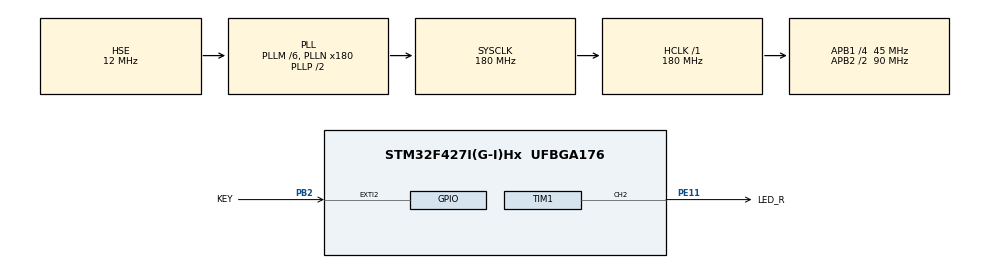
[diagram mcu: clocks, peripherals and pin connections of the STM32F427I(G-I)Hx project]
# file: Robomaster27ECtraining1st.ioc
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IWDG.Prescaler=IWDG_PRESCALER_16
IWDG.Reload=4000-1
Mcu.Family=STM32F4
Mcu.Name=STM32F427I(G-I)Hx
Mcu.Package=UFBGA176
NVIC.EXTI2_IRQn=true\:0\:0\:false\:false\:true\:true\:true\:true
NVIC.PriorityGroup=NVIC_PRIORITYGROUP_4
NVIC.TIM1_UP_TIM10_IRQn=true\:0\:0\:false\:false\:true\:true\:true\:true
PA13.Mode=Serial_Wire
PA13.Signal=SYS_JTMS-SWDIO
PA14.Mode=Serial_Wire
PA14.Signal=SYS_JTCK-SWCLK
PB2/BOOT1.GPIO_Label=KEY
PB2/BOOT1.GPIO_PuPd=GPIO_PULLDOWN
PB2/BOOT1.Signal=GPXTI2
PE11.GPIO_Label=LED_R
PE11.Signal=S_TIM1_CH2
PH0/OSC_IN.Mode=HSE-External-Oscillator
PH0/OSC_IN.Signal=RCC_OSC_IN
PH1/OSC_OUT.Mode=HSE-External-Oscillator
PH1/OSC_OUT.Signal=RCC_OSC_OUT
ProjectManager.HeapSize=0x200
ProjectManager.StackSize=0x400
ProjectManager.TargetToolchain=MDK-ARM V5.32
RCC.48MHZClocksFreq_Value=90000000
RCC.AHBFreq_Value=180000000
RCC.APB1CLKDivider=RCC_HCLK_DIV4
RCC.APB1Freq_Value=45000000
RCC.APB1TimFreq_Value=90000000
RCC.APB2CLKDivider=RCC_HCLK_DIV2
RCC.APB2Freq_Value=90000000
RCC.APB2TimFreq_Value=180000000
RCC.CortexFreq_Value=180000000
RCC.HCLKFreq_Value=180000000
RCC.HSE_VALUE=12000000
RCC.HSI_VALUE=16000000
RCC.LSE_VALUE=32768
RCC.PLLM=6
RCC.PLLN=180
RCC.PLLSourceVirtual=RCC_PLLSOURCE_HSE
RCC.SYSCLKFreq_VALUE=180000000
RCC.SYSCLKSource=RCC_SYSCLKSOURCE_PLLCLK
RCC.VCOOutputFreq_Value=360000000
SH.S_TIM1_CH2.0=TIM1_CH2,PWM Generation2 CH2
TIM1.Channel-PWM\ Generation2\ CH2=TIM_CHANNEL_2
TIM1.OCMode_PWM-PWM\ Generation2\ CH2=TIM_OCMODE_PWM2
TIM1.Period=1000-1
TIM1.Prescaler=180-1
TIM1.Pulse-PWM\ Generation2\ CH2=500
VP_IWDG_VS_IWDG.Mode=IWDG_Activate
VP_TIM1_VS_ClockSourceINT.Mode=Internal
board=custom

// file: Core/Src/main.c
/* USER CODE BEGIN Header */
/**
  ******************************************************************************
  * @file           : main.c
  * @brief          : Main program body
  ******************************************************************************
  * @attention
  *
  * Copyright (c) 2026 STMicroelectronics.
  * All rights reserved.
  *
  * This software is licensed under terms that can be found in the LICENSE file
  * in the root directory of this software component.
  * If no LICENSE file comes with this software, it is provided AS-IS.
  *
  ******************************************************************************
  */
/* USER CODE END Header */
#include "main.h"
#include "iwdg.h"
#include "tim.h"
#include "gpio.h"

uint8_t requested_mode;
uint32_t tick;
uint32_t cur_tick, last_tick;
uint32_t start_tick;
/* USER CODE END PV */

void SystemClock_Config(void);

int main(void)
{

  /* MCU Configuration--------------------------------------------------------*/

  /* Reset of all peripherals, Initializes the Flash interface and the Systick. */
  HAL_Init();

  /* Configure the system clock */
  SystemClock_Config();

  /* Initialize all configured peripherals */
  MX_GPIO_Init();
  MX_TIM1_Init();
  MX_IWDG_Init();
  /* USER CODE BEGIN 2 */
  HAL_TIM_Base_Start_IT(&htim1);
  HAL_TIM_PWM_Start(&htim1, TIM_CHANNEL_2);
  // HAL_TIM_PWM_Start(&htim12, TIM_CHANNEL_1);
  /* USER CODE END 2 */

  /* Infinite loop */
  /* USER CODE BEGIN WHILE */
  while (1)
  {
    cur_tick = HAL_GetTick();
    if (requested_mode == 0)
    {
      __HAL_TIM_SET_COMPARE(&htim1, TIM_CHANNEL_2, 0);
    }
    else if (requested_mode == 1)
    {
      tick += (cur_tick - last_tick);
      tick %= 2000;
      if (tick <= 1000)
        __HAL_TIM_SET_COMPARE(&htim1, TIM_CHANNEL_2, tick);
      else
        __HAL_TIM_SET_COMPARE(&htim1, TIM_CHANNEL_2, 2000-tick);
    }
    else if (requested_mode == 2)
    {
      tick += (cur_tick - last_tick);
      tick %= 1000;
      if (tick <= 500)
      {
        __HAL_TIM_SET_COMPARE(&htim1, TIM_CHANNEL_2, 1000);
      }
      else
      {
        __HAL_TIM_SET_COMPARE(&htim1, TIM_CHANNEL_2, 0);
      }
    }
    last_tick = cur_tick;
    HAL_IWDG_Refresh(&hiwdg);
  }
    /* USER CODE END WHILE */

}

void SystemClock_Config(void)
{
  RCC_OscInitTypeDef RCC_OscInitStruct = {0};
  RCC_ClkInitTypeDef RCC_ClkInitStruct = {0};

  /** Configure the main internal regulator output voltage
  */
  __HAL_RCC_PWR_CLK_ENABLE();
  __HAL_PWR_VOLTAGESCALING_CONFIG(PWR_REGULATOR_VOLTAGE_SCALE1);

  /** Initializes the RCC Oscillators according to the specified parameters
  * in the RCC_OscInitTypeDef structure.
  */
  RCC_OscInitStruct.OscillatorType = RCC_OSCILLATORTYPE_LSI|RCC_OSCILLATORTYPE_HSE;
  RCC_OscInitStruct.HSEState = RCC_HSE_ON;
  RCC_OscInitStruct.LSIState = RCC_LSI_ON;
  RCC_OscInitStruct.PLL.PLLState = RCC_PLL_ON;
  RCC_OscInitStruct.PLL.PLLSource = RCC_PLLSOURCE_HSE;
  RCC_OscInitStruct.PLL.PLLM = 6;
  RCC_OscInitStruct.PLL.PLLN = 180;
  RCC_OscInitStruct.PLL.PLLP = RCC_PLLP_DIV2;
  RCC_OscInitStruct.PLL.PLLQ = 4;
  if (HAL_RCC_OscConfig(&RCC_OscInitStruct) != HAL_OK)
  {
    Error_Handler();
  }

  /** Activate the Over-Drive mode
  */
  if (HAL_PWREx_EnableOverDrive() != HAL_OK)
  {
    Error_Handler();
  }

  /** Initializes the CPU, AHB and APB buses clocks
  */
  RCC_ClkInitStruct.ClockType = RCC_CLOCKTYPE_HCLK|RCC_CLOCKTYPE_SYSCLK
                              |RCC_CLOCKTYPE_PCLK1|RCC_CLOCKTYPE_PCLK2;
  RCC_ClkInitStruct.SYSCLKSource = RCC_SYSCLKSOURCE_PLLCLK;
  RCC_ClkInitStruct.AHBCLKDivider = RCC_SYSCLK_DIV1;
  RCC_ClkInitStruct.APB1CLKDivider = RCC_HCLK_DIV4;
  RCC_ClkInitStruct.APB2CLKDivider = RCC_HCLK_DIV2;

  if (HAL_RCC_ClockConfig(&RCC_ClkInitStruct, FLASH_LATENCY_5) != HAL_OK)
  {
    Error_Handler();
  }
}

void Error_Handler(void)
{
  __disable_irq();
  while (1)
  {
  }
}
